# SWM341 register map
File version: 1.0
CPU: CM0 r1p0, little endian, MPU, FPU, 2 interrupt priority bits
Registers are 32-bit, read-write, no defined reset value unless marked. A register's access mark holds for its fields unless they carry their own. Offsets are from the block's base; [hi:lo] are bit positions; lines under a group give offsets from that group; {n}, {i} and the like mark numbered series; 'fields as' and 'values as' point back to an identical list.

## ADC0 — Registers group
Base 0x40049000
Same registers: ADC1 0x40049800
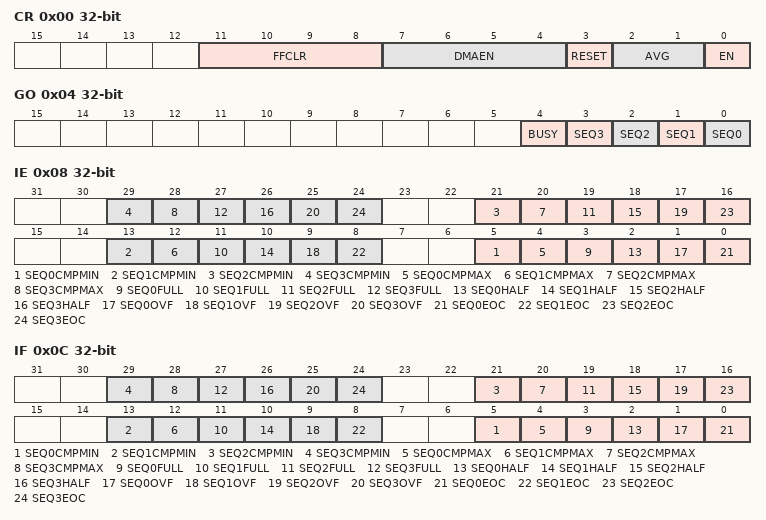
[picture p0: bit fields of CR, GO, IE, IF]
0x00 CR
  [11:8] FFCLR, [7:4] DMAEN, [3] RESET, [2:1] AVG, [0] EN
0x04 GO
  [4] BUSY, [n] SEQ{n} (n=0..3)
0x08 IE
  [8n+5] SEQ{n}CMPMIN (n=0..3), [8n+4] SEQ{n}CMPMAX (n=0..3), [8n+3] SEQ{n}FULL (n=0..3), [8n+2] SEQ{n}HALF (n=0..3), [8n+1] SEQ{n}OVF (n=0..3), [8n] SEQ{n}EOC (n=0..3)
0x0C IF
  fields as IE
{0x10+0x10*i} SEQ{i} group (i=0..3) — register cluster
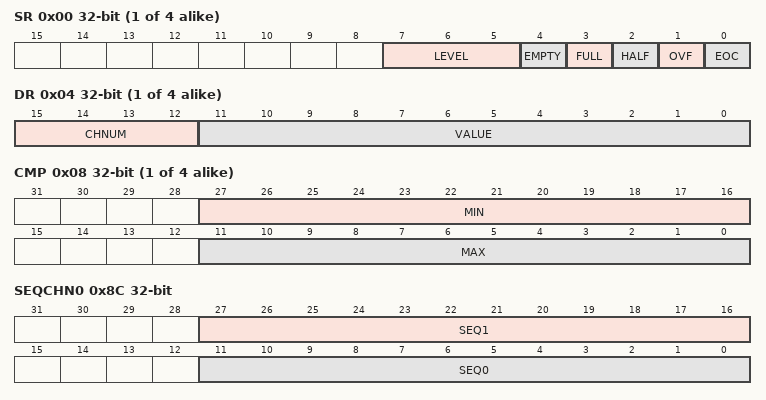
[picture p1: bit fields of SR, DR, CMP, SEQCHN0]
  0x00 SR
    [7:5] LEVEL, [4] EMPTY, [3] FULL, [2] HALF, [1] OVF, [0] EOC
  0x04 DR
    [15:12] CHNUM, [11:0] VALUE
  0x08 CMP
    [27:16] MIN, [11:0] MAX
0x8C SEQCHN0
  [27:16] SEQ1, [11:0] SEQ0
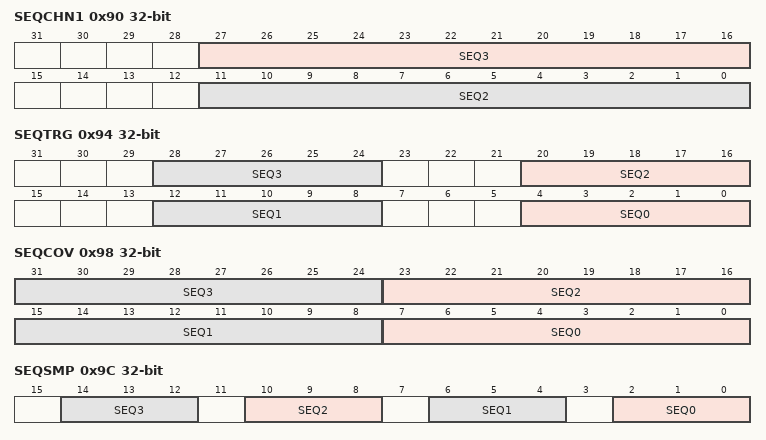
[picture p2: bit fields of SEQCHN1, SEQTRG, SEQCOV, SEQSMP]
0x90 SEQCHN1
  [27:16] SEQ3, [11:0] SEQ2
0x94 SEQTRG
  [8n+4:8n] SEQ{n} (n=0..3)
0x98 SEQCOV
  [8n+7:8n] SEQ{n} (n=0..3)
0x9C SEQSMP
  [4n+2:4n] SEQ{n} (n=0..3)
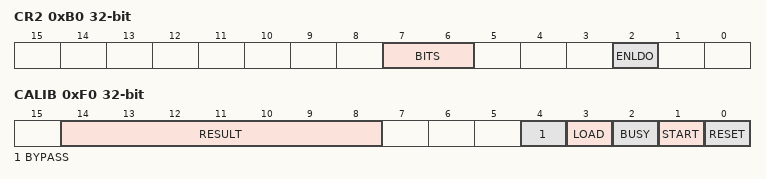
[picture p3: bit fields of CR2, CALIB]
0xB0 CR2
  [7:6] BITS, [2] ENLDO
0xF0 CALIB
  [14:8] RESULT, [4] BYPASS, [3] LOAD, [2] BUSY, [1] START, [0] RESET

## PWM0 — Registers group
Base 0x40046000
Same registers: PWM1 0x40046080, PWM2 0x40046100, PWM3 0x40046180, PWM4 0x40046200
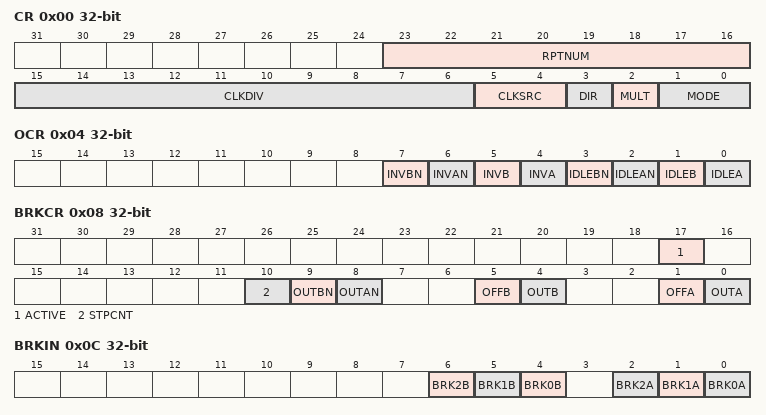
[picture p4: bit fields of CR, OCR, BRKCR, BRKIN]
0x00 CR
  [23:16] RPTNUM, [15:6] CLKDIV, [5:4] CLKSRC, [3] DIR, [2] MULT, [1:0] MODE
0x04 OCR
  [7] INVBN, [6] INVAN, [5] INVB, [4] INVA, [3] IDLEBN, [2] IDLEAN, [1] IDLEB, [0] IDLEA
0x08 BRKCR
  [17] ACTIVE, [10] STPCNT, [9] OUTBN, [8] OUTAN, [5] OFFB, [4] OUTB, [1] OFFA, [0] OUTA
0x0C BRKIN
  [6] BRK2B, [5] BRK1B, [4] BRK0B, [2] BRK2A, [1] BRK1A, [0] BRK0A
0x20 PERIOD
0x24 CMPA
0x28 CMPB
0x2C DZA
0x30 DZB
0x34 CMPA2
0x38 CMPB2
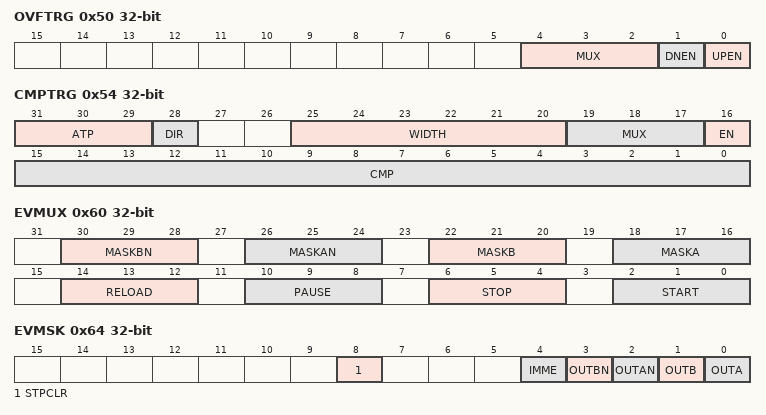
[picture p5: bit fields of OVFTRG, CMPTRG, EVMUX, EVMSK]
0x50 OVFTRG
  [4:2] MUX, [1] DNEN, [0] UPEN
0x54 CMPTRG
  [31:29] ATP, [28] DIR, [25:20] WIDTH, [19:17] MUX, [16] EN, [15:0] CMP
0x60 EVMUX
  [30:28] MASKBN, [26:24] MASKAN, [22:20] MASKB, [18:16] MASKA, [14:12] RELOAD, [10:8] PAUSE, [6:4] STOP, [2:0] START
0x64 EVMSK
  [8] STPCLR, [4] IMME, [3] OUTBN, [2] OUTAN, [1] OUTB, [0] OUTA
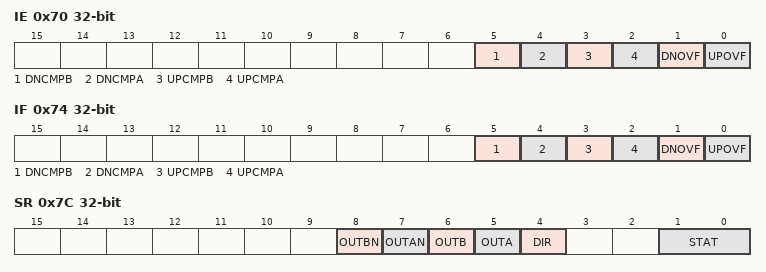
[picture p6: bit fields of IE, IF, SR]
0x70 IE
  [5] DNCMPB, [4] DNCMPA, [3] UPCMPB, [2] UPCMPA, [1] DNOVF, [0] UPOVF
0x74 IF
  [5] DNCMPB, [4] DNCMPA, [3] UPCMPB, [2] UPCMPA, [1] DNOVF, [0] UPOVF
0x78 VALUE
0x7C SR
  [8] OUTBN, [7] OUTAN, [6] OUTB, [5] OUTA, [4] DIR, [1:0] STAT

## PWMG — Registers group
Base 0x40046400
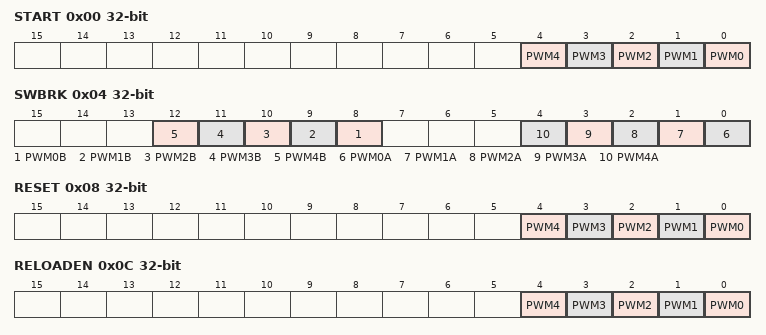
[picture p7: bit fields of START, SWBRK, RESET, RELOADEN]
0x00 START
  [n] PWM{n} (n=0..4)
0x04 SWBRK
  [n+8] PWM{n}B (n=0..4), [n] PWM{n}A (n=0..4)
0x08 RESET
  [n] PWM{n} (n=0..4)
0x0C RELOADEN
  [n] PWM{n} (n=0..4)
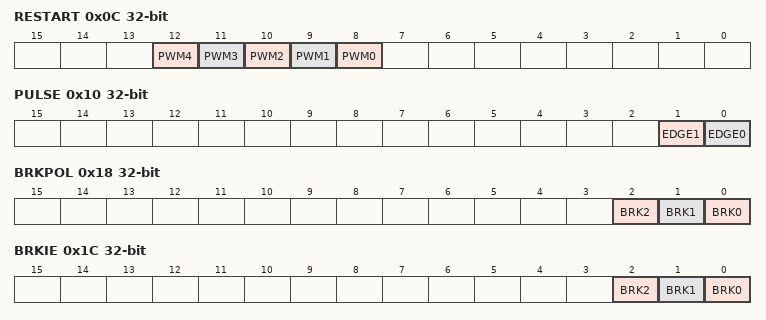
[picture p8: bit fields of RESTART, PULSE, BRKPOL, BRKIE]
0x0C RESTART (alternate view of RELOADEN)
  [n+8] PWM{n} (n=0..4)
0x10 PULSE
  [1] EDGE1, [0] EDGE0
0x14 FILTER
0x18 BRKPOL
  [2] BRK2, [1] BRK1, [0] BRK0
0x1C BRKIE
  [2] BRK2, [1] BRK1, [0] BRK0
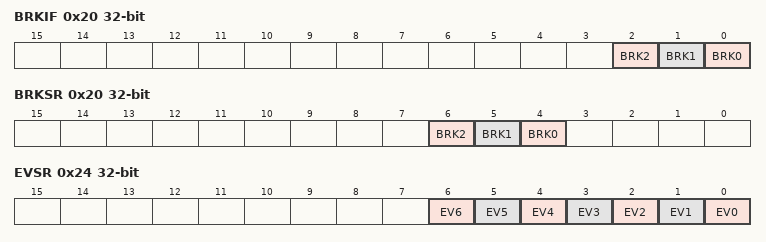
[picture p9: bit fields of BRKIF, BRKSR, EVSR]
0x20 BRKIF
  [2] BRK2, [1] BRK1, [0] BRK0
0x20 BRKSR (alternate view of BRKIF)
  [6] BRK2, [5] BRK1, [4] BRK0
0x24 EVSR
  [n] EV{n} (n=0..6)

## CAN0 — Registers group
Base 0x400A8000
Same registers: CAN1 0x400A8800
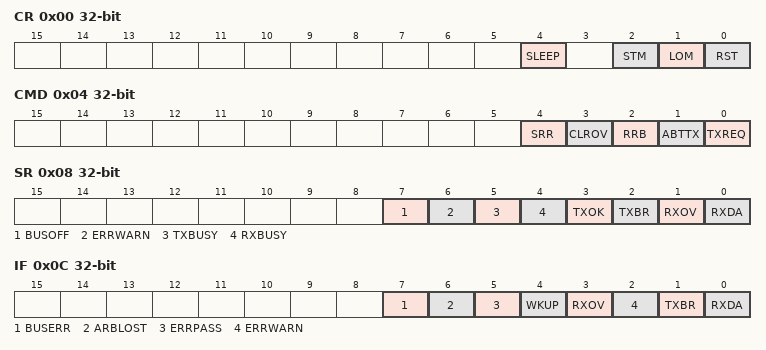
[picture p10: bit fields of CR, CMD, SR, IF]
0x00 CR
  [4] SLEEP, [2] STM, [1] LOM, [0] RST
0x04 CMD wo
  [4] SRR, [3] CLROV, [2] RRB, [1] ABTTX, [0] TXREQ
0x08 SR ro
  [7] BUSOFF, [6] ERRWARN, [5] TXBUSY, [4] RXBUSY, [3] TXOK, [2] TXBR, [1] RXOV, [0] RXDA
0x0C IF
  [7] BUSERR, [6] ARBLOST, [5] ERRPASS, [4] WKUP, [3] RXOV, [2] ERRWARN, [1] TXBR, [0] RXDA
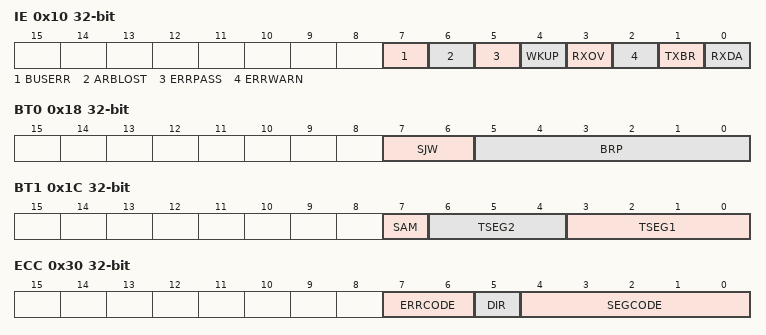
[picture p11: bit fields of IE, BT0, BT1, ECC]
0x10 IE
  fields as IF
0x14 BT2
  [3:0] BRP
0x18 BT0
  [7:6] SJW, [5:0] BRP
0x1C BT1
  [7] SAM, [6:4] TSEG2, [3:0] TSEG1
0x24 AFM
0x28 AFE
0x2C ALC ro
0x30 ECC ro
  [7:6] ERRCODE, [5] DIR, [4:0] SEGCODE
0x34 EWLIM
0x38 RXERR
0x3C TXERR
0x40 FRAME group — register cluster
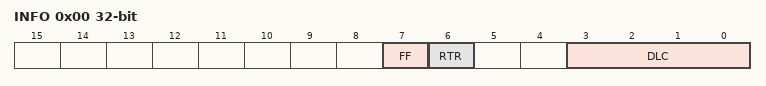
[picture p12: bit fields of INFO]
  0x00 INFO
    [7] FF, [6] RTR, [3:0] DLC
  {0x4+4j} DATA[{j}] (j=0..11)
0x74 RMCNT ro
{0x300+4i} ACR[{i}] (i=0..15)
{0x380+4i} AMR[{i}] (i=0..15)

## USBD — Registers group
Base 0x40005000
{0x0+4i} TXBUF0_[{i}] (i=0..255)
{0x400+4i} TXBUF1_[{i}] (i=0..255)
{0x800+4i} TXBUF2_[{i}] (i=0..255)
{0xC00+4i} TXBUF3_[{i}] (i=0..255)
{0x1000+4i} TXBUF4_[{i}] (i=0..255)
{0x1400+4i} TXBUF5_[{i}] (i=0..255)
{0x1800+4i} TXBUF6_[{i}] (i=0..255)
{0x1C00+4i} TXBUF7_[{i}] (i=0..255)
{0x2000+4i} TXBUF8_[{i}] (i=0..255)
{0x2400+4i} TXBUF9_[{i}] (i=0..255)
{0x2800+4i} TXBUF10_[{i}] (i=0..255)
{0x2C00+4i} TXBUF11_[{i}] (i=0..255)
{0x3000+4i} TXBUF12_[{i}] (i=0..255)
{0x3400+4i} TXBUF13_[{i}] (i=0..255)
{0x3800+4i} TXBUF14_[{i}] (i=0..255)
{0x3C00+4i} TXBUF15_[{i}] (i=0..255)
{0x4000+4i} RXBUF[{i}] (i=0..255)
{0x4400+0x10*i} INEP{i} group (i=0..15) — register cluster
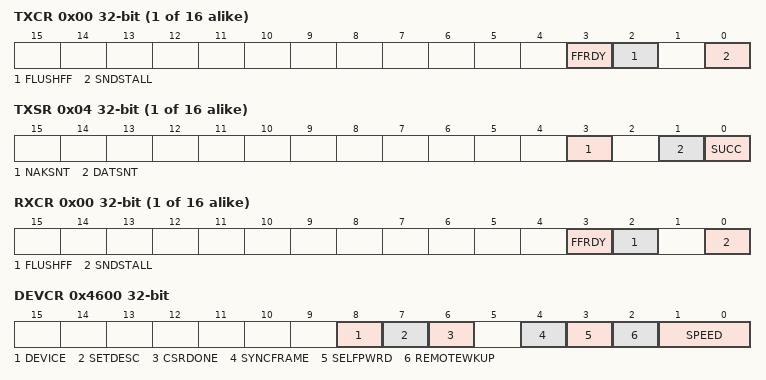
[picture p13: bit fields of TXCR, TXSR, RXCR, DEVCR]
  0x00 TXCR
    [3] FFRDY, [2] FLUSHFF, [0] SNDSTALL
  0x04 TXSR
    [3] NAKSNT, [1] DATSNT, [0] SUCC
  0x0C TXTRSZ
{0x4500+0x10*i} OUTEP{i} group (i=0..15) — register cluster
  0x00 RXCR
    [3] FFRDY, [2] FLUSHFF, [0] SNDSTALL
0x4600 DEVCR
  [8] DEVICE, [7] SETDESC, [6] CSRDONE, [4] SYNCFRAME, [3] SELFPWRD, [2] REMOTEWKUP, [1:0] SPEED
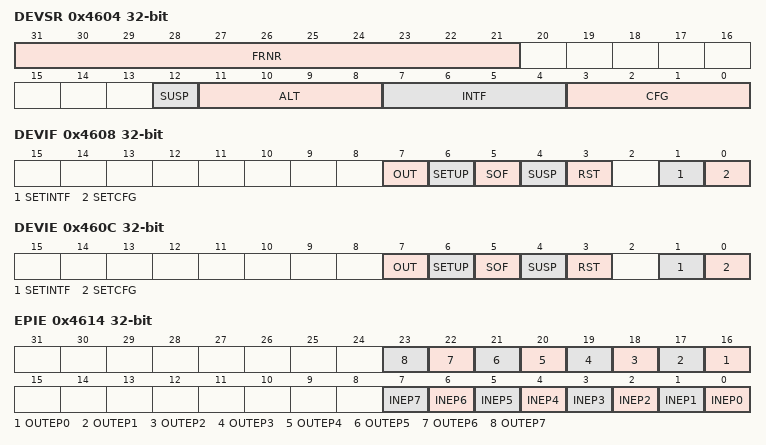
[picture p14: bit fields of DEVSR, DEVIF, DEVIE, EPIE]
0x4604 DEVSR ro
  [31:21] FRNR, [12] SUSP, [11:8] ALT, [7:4] INTF, [3:0] CFG
0x4608 DEVIF
  [7] OUT, [6] SETUP, [5] SOF, [4] SUSP, [3] RST, [1] SETINTF, [0] SETCFG
0x460C DEVIE
  fields as DEVIF
0x4614 EPIE
  [n+16] OUTEP{n} (n=0..7), [n] INEP{n} (n=0..7)
0x4618 FFTHR
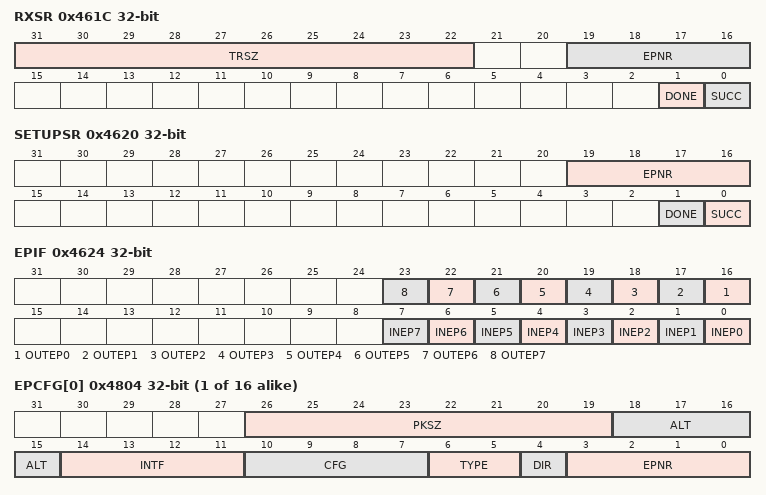
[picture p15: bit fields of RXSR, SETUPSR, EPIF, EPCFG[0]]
0x461C RXSR
  [31:22] TRSZ, [19:16] EPNR, [1] DONE, [0] SUCC
0x4620 SETUPSR
  [19:16] EPNR, [1] DONE, [0] SUCC
0x4624 EPIF
  [n+16] OUTEP{n} (n=0..7), [n] INEP{n} (n=0..7)
0x4628 FRAMENR
0x4700 SETUPD1
0x4704 SETUPD2
{0x4804+4i} EPCFG[{i}] (i=0..15)
  [26:19] PKSZ, [18:15] ALT, [14:11] INTF, [10:7] CFG, [6:5] TYPE, [4] DIR, [3:0] EPNR
